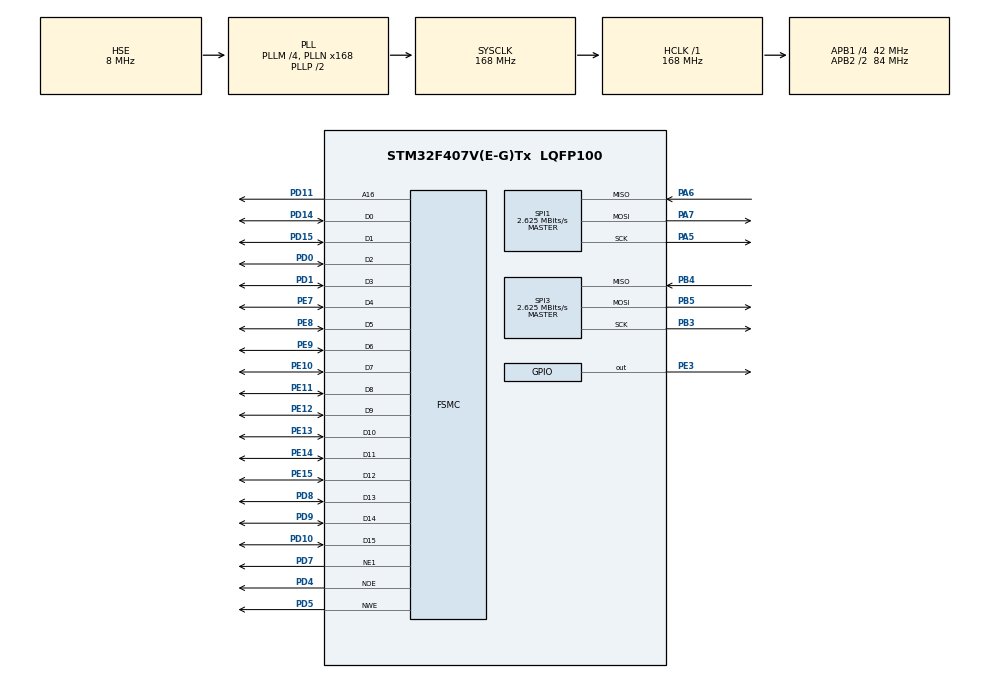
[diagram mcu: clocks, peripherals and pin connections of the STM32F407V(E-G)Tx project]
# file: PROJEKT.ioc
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Mcu.Family=STM32F4
Mcu.Name=STM32F407V(E-G)Tx
Mcu.Package=LQFP100
NVIC.PriorityGroup=NVIC_PRIORITYGROUP_4
PA5.Mode=Full_Duplex_Master
PA5.Signal=SPI1_SCK
PA6.Mode=Full_Duplex_Master
PA6.Signal=SPI1_MISO
PA7.Mode=Full_Duplex_Master
PA7.Signal=SPI1_MOSI
PB3.Mode=Full_Duplex_Master
PB3.Signal=SPI3_SCK
PB4.Mode=Full_Duplex_Master
PB4.Signal=SPI3_MISO
PB5.Mode=Full_Duplex_Master
PB5.Signal=SPI3_MOSI
PD0.Mode=16b-d1
PD0.Signal=FSMC_D2
PD1.Mode=16b-d1
PD1.Signal=FSMC_D3
PD10.Mode=16b-d1
PD10.Signal=FSMC_D15
PD11.Mode=A16_1
PD11.Signal=FSMC_A16
PD14.Mode=16b-d1
PD14.Signal=FSMC_D0
PD15.Mode=16b-d1
PD15.Signal=FSMC_D1
PD4.Mode=Lcd1
PD4.Signal=FSMC_NOE
PD5.Mode=Lcd1
PD5.Signal=FSMC_NWE
PD7.Mode=NorPsramChipSelect1_1
PD7.Signal=FSMC_NE1
PD8.Mode=16b-d1
PD8.Signal=FSMC_D13
PD9.Mode=16b-d1
PD9.Signal=FSMC_D14
PE10.Mode=16b-d1
PE10.Signal=FSMC_D7
PE11.Mode=16b-d1
PE11.Signal=FSMC_D8
PE12.Mode=16b-d1
PE12.Signal=FSMC_D9
PE13.Mode=16b-d1
PE13.Signal=FSMC_D10
PE14.Mode=16b-d1
PE14.Signal=FSMC_D11
PE15.Mode=16b-d1
PE15.Signal=FSMC_D12
PE3.Signal=GPIO_Output
PE7.Mode=16b-d1
PE7.Signal=FSMC_D4
PE8.Mode=16b-d1
PE8.Signal=FSMC_D5
PE9.Mode=16b-d1
PE9.Signal=FSMC_D6
PH0-OSC_IN.Mode=HSE-External-Oscillator
PH0-OSC_IN.Signal=RCC_OSC_IN
PH1-OSC_OUT.Mode=HSE-External-Oscillator
PH1-OSC_OUT.Signal=RCC_OSC_OUT
ProjectManager.HeapSize=0x200
ProjectManager.StackSize=0x400
ProjectManager.TargetToolchain=STM32CubeIDE
RCC.48MHZClocksFreq_Value=84000000
RCC.AHBFreq_Value=168000000
RCC.APB1CLKDivider=RCC_HCLK_DIV4
RCC.APB1Freq_Value=42000000
RCC.APB1TimFreq_Value=84000000
RCC.APB2CLKDivider=RCC_HCLK_DIV2
RCC.APB2Freq_Value=84000000
RCC.APB2TimFreq_Value=168000000
RCC.CortexFreq_Value=168000000
RCC.HCLKFreq_Value=168000000
RCC.HSE_VALUE=8000000
RCC.HSI_VALUE=16000000
RCC.LSE_VALUE=32768
RCC.PLLM=4
RCC.PLLN=168
RCC.PLLSourceVirtual=RCC_PLLSOURCE_HSE
RCC.SYSCLKFreq_VALUE=168000000
RCC.SYSCLKSource=RCC_SYSCLKSOURCE_PLLCLK
RCC.VCOOutputFreq_Value=336000000
SPI1.BaudRatePrescaler=SPI_BAUDRATEPRESCALER_32
SPI1.CalculateBaudRate=2.625 MBits/s
SPI1.Direction=SPI_DIRECTION_2LINES
SPI1.Mode=SPI_MODE_MASTER
SPI1.VirtualType=VM_MASTER
SPI3.BaudRatePrescaler=SPI_BAUDRATEPRESCALER_16
SPI3.CalculateBaudRate=2.625 MBits/s
SPI3.Direction=SPI_DIRECTION_2LINES
SPI3.Mode=SPI_MODE_MASTER
SPI3.VirtualType=VM_MASTER
board=custom

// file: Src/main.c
/* USER CODE BEGIN Header */
/**
  ******************************************************************************
  * @file           : main.c
  * @brief          : Main program body
  ******************************************************************************
  * @attention
  *
  * <h2><center>&copy; Copyright (c) 2020 STMicroelectronics.
  * All rights reserved.</center></h2>
  *
  * This software component is licensed by ST under BSD 3-Clause license,
  * the "License"; You may not use this file except in compliance with the
  * License. You may obtain a copy of the License at:
  *                        opensource.org/licenses/BSD-3-Clause
  *
  ******************************************************************************
  */
/* USER CODE END Header */

#include "main.h"

/* USER CODE BEGIN Includes */
//#include "ff.h"
#include "gra.h"
/* USER CODE END Includes */

SPI_HandleTypeDef hspi1;
SPI_HandleTypeDef hspi3;

SRAM_HandleTypeDef hsram1;

void SystemClock_Config(void);
static void MX_GPIO_Init(void);
static void MX_SPI1_Init(void);
static void MX_FSMC_Init(void);
static void MX_SPI3_Init(void);

int main(void)
{

  /* MCU Configuration--------------------------------------------------------*/

  /* Reset of all peripherals, Initializes the Flash interface and the Systick. */
  HAL_Init();

  /* USER CODE BEGIN Init */
  ili9325_Init();
  LISInit();
  /* USER CODE END Init */

  /* Configure the system clock */
  SystemClock_Config();

  /* Initialize all configured peripherals */
  MX_GPIO_Init();
  MX_SPI1_Init();
  MX_FSMC_Init();
  MX_SPI3_Init();
  /* USER CODE BEGIN 2 */
  SetRanking();
  ili9325_DisplayOn();
  StartExitScreen();
  DrawMenu(-1);
  UseMenu();
  /* USER CODE END 2 */

  /* Infinite loop */
  /* USER CODE BEGIN WHILE */
  while (1)
  {
	  break;
    /* USER CODE END WHILE */

  }
}

void SystemClock_Config(void)
{
  RCC_OscInitTypeDef RCC_OscInitStruct = {0};
  RCC_ClkInitTypeDef RCC_ClkInitStruct = {0};

  /** Configure the main internal regulator output voltage
  */
  __HAL_RCC_PWR_CLK_ENABLE();
  __HAL_PWR_VOLTAGESCALING_CONFIG(PWR_REGULATOR_VOLTAGE_SCALE1);
  /** Initializes the CPU, AHB and APB busses clocks
  */
  RCC_OscInitStruct.OscillatorType = RCC_OSCILLATORTYPE_HSE;
  RCC_OscInitStruct.HSEState = RCC_HSE_ON;
  RCC_OscInitStruct.PLL.PLLState = RCC_PLL_ON;
  RCC_OscInitStruct.PLL.PLLSource = RCC_PLLSOURCE_HSE;
  RCC_OscInitStruct.PLL.PLLM = 4;
  RCC_OscInitStruct.PLL.PLLN = 168;
  RCC_OscInitStruct.PLL.PLLP = RCC_PLLP_DIV2;
  RCC_OscInitStruct.PLL.PLLQ = 4;
  if (HAL_RCC_OscConfig(&RCC_OscInitStruct) != HAL_OK)
  {
    Error_Handler();
  }
  /** Initializes the CPU, AHB and APB busses clocks
  */
  RCC_ClkInitStruct.ClockType = RCC_CLOCKTYPE_HCLK|RCC_CLOCKTYPE_SYSCLK
                              |RCC_CLOCKTYPE_PCLK1|RCC_CLOCKTYPE_PCLK2;
  RCC_ClkInitStruct.SYSCLKSource = RCC_SYSCLKSOURCE_PLLCLK;
  RCC_ClkInitStruct.AHBCLKDivider = RCC_SYSCLK_DIV1;
  RCC_ClkInitStruct.APB1CLKDivider = RCC_HCLK_DIV4;
  RCC_ClkInitStruct.APB2CLKDivider = RCC_HCLK_DIV2;

  if (HAL_RCC_ClockConfig(&RCC_ClkInitStruct, FLASH_LATENCY_5) != HAL_OK)
  {
    Error_Handler();
  }
}

static void MX_SPI1_Init(void)
{

  /* SPI1 parameter configuration*/
  hspi1.Instance = SPI1;
  hspi1.Init.Mode = SPI_MODE_MASTER;
  hspi1.Init.Direction = SPI_DIRECTION_2LINES;
  hspi1.Init.DataSize = SPI_DATASIZE_8BIT;
  hspi1.Init.CLKPolarity = SPI_POLARITY_LOW;
  hspi1.Init.CLKPhase = SPI_PHASE_1EDGE;
  hspi1.Init.NSS = SPI_NSS_SOFT;
  hspi1.Init.BaudRatePrescaler = SPI_BAUDRATEPRESCALER_32;
  hspi1.Init.FirstBit = SPI_FIRSTBIT_MSB;
  hspi1.Init.TIMode = SPI_TIMODE_DISABLE;
  hspi1.Init.CRCCalculation = SPI_CRCCALCULATION_DISABLE;
  hspi1.Init.CRCPolynomial = 10;
  if (HAL_SPI_Init(&hspi1) != HAL_OK)
  {
    Error_Handler();
  }

}

static void MX_SPI3_Init(void)
{

  /* SPI3 parameter configuration*/
  hspi3.Instance = SPI3;
  hspi3.Init.Mode = SPI_MODE_MASTER;
  hspi3.Init.Direction = SPI_DIRECTION_2LINES;
  hspi3.Init.DataSize = SPI_DATASIZE_8BIT;
  hspi3.Init.CLKPolarity = SPI_POLARITY_LOW;
  hspi3.Init.CLKPhase = SPI_PHASE_1EDGE;
  hspi3.Init.NSS = SPI_NSS_SOFT;
  hspi3.Init.BaudRatePrescaler = SPI_BAUDRATEPRESCALER_16;
  hspi3.Init.FirstBit = SPI_FIRSTBIT_MSB;
  hspi3.Init.TIMode = SPI_TIMODE_DISABLE;
  hspi3.Init.CRCCalculation = SPI_CRCCALCULATION_DISABLE;
  hspi3.Init.CRCPolynomial = 10;
  if (HAL_SPI_Init(&hspi3) != HAL_OK)
  {
    Error_Handler();
  }

}

static void MX_GPIO_Init(void)
{
  GPIO_InitTypeDef GPIO_InitStruct = {0};

  /* GPIO Ports Clock Enable */
  __HAL_RCC_GPIOE_CLK_ENABLE();
  __HAL_RCC_GPIOH_CLK_ENABLE();
  __HAL_RCC_GPIOA_CLK_ENABLE();
  __HAL_RCC_GPIOD_CLK_ENABLE();
  __HAL_RCC_GPIOB_CLK_ENABLE();

  /*Configure GPIO pin Output Level */
  HAL_GPIO_WritePin(GPIOE, GPIO_PIN_3, GPIO_PIN_RESET);

  /*Configure GPIO pin : PE3 */
  GPIO_InitStruct.Pin = GPIO_PIN_3;
  GPIO_InitStruct.Mode = GPIO_MODE_OUTPUT_PP;
  GPIO_InitStruct.Pull = GPIO_NOPULL;
  GPIO_InitStruct.Speed = GPIO_SPEED_FREQ_LOW;
  HAL_GPIO_Init(GPIOE, &GPIO_InitStruct);

}

/* FSMC initialization function */
static void MX_FSMC_Init(void)
{

  FSMC_NORSRAM_TimingTypeDef Timing = {0};

  /** Perform the SRAM1 memory initialization sequence
  */
  hsram1.Instance = FSMC_NORSRAM_DEVICE;
  hsram1.Extended = FSMC_NORSRAM_EXTENDED_DEVICE;
  /* hsram1.Init */
  hsram1.Init.NSBank = FSMC_NORSRAM_BANK1;
  hsram1.Init.DataAddressMux = FSMC_DATA_ADDRESS_MUX_DISABLE;
  hsram1.Init.MemoryType = FSMC_MEMORY_TYPE_SRAM;
  hsram1.Init.MemoryDataWidth = FSMC_NORSRAM_MEM_BUS_WIDTH_16;
  hsram1.Init.BurstAccessMode = FSMC_BURST_ACCESS_MODE_DISABLE;
  hsram1.Init.WaitSignalPolarity = FSMC_WAIT_SIGNAL_POLARITY_LOW;
  hsram1.Init.WrapMode = FSMC_WRAP_MODE_DISABLE;
  hsram1.Init.WaitSignalActive = FSMC_WAIT_TIMING_BEFORE_WS;
  hsram1.Init.WriteOperation = FSMC_WRITE_OPERATION_ENABLE;
  hsram1.Init.WaitSignal = FSMC_WAIT_SIGNAL_DISABLE;
  hsram1.Init.ExtendedMode = FSMC_EXTENDED_MODE_DISABLE;
  hsram1.Init.AsynchronousWait = FSMC_ASYNCHRONOUS_WAIT_DISABLE;
  hsram1.Init.WriteBurst = FSMC_WRITE_BURST_DISABLE;
  hsram1.Init.PageSize = FSMC_PAGE_SIZE_NONE;
  /* Timing */
  Timing.AddressSetupTime = 15;
  Timing.AddressHoldTime = 15;
  Timing.DataSetupTime = 255;
  Timing.BusTurnAroundDuration = 15;
  Timing.CLKDivision = 16;
  Timing.DataLatency = 17;
  Timing.AccessMode = FSMC_ACCESS_MODE_A;
  /* ExtTiming */

  if (HAL_SRAM_Init(&hsram1, &Timing, NULL) != HAL_OK)
  {
    Error_Handler( );
  }

}

void Error_Handler(void)
{
}

/************************ (C) COPYRIGHT STMicroelectronics *****END OF FILE****/
